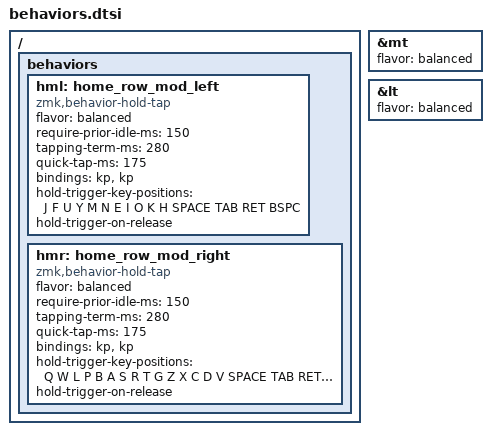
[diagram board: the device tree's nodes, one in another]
&mt { flavor = "balanced"; };

&lt { flavor = "balanced"; };

/ {
    behaviors {
        hml: home_row_mod_left {
            compatible = "zmk,behavior-hold-tap";
            #binding-cells = <2>;
            flavor = "balanced";
            require-prior-idle-ms = <150>;
            tapping-term-ms = <280>;
            quick-tap-ms = <175>;
            bindings = <&kp>, <&kp>;

            hold-trigger-key-positions = < J F U Y M N E I O K H SPACE TAB RET BSPC>; // List of keys on the right side of the keyboard
            hold-trigger-on-release;
        };

        hmr: home_row_mod_right {
            compatible = "zmk,behavior-hold-tap";
            #binding-cells = <2>;
            flavor = "balanced";
            require-prior-idle-ms = <150>;
            tapping-term-ms = <280>;
            quick-tap-ms = <175>;
            bindings = <&kp>, <&kp>;

            hold-trigger-key-positions = < Q W L P B A S R T G Z X C D V SPACE TAB RET BSPC>; // List of keys on the left side of the keyboard
            hold-trigger-on-release;
        };
    };
};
